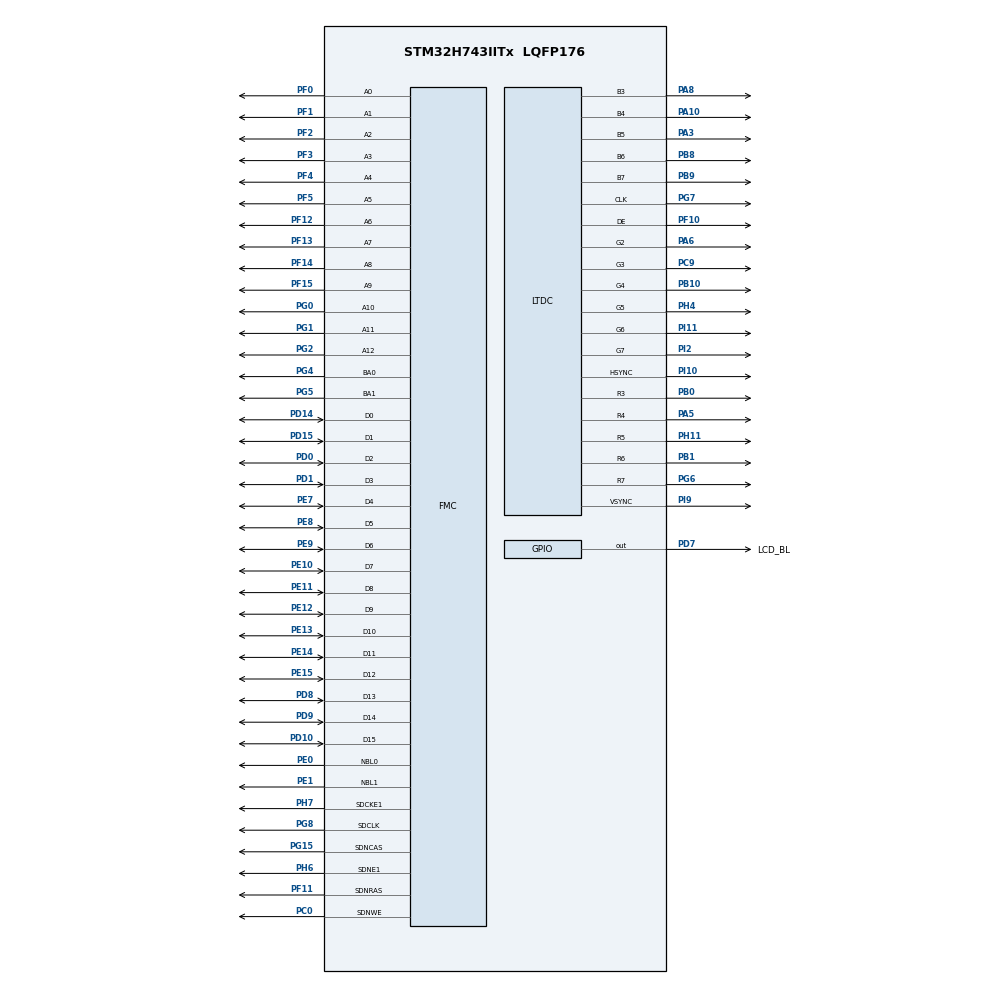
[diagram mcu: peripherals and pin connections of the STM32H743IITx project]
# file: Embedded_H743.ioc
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CORTEX_M7.default_mode_Activation=1
DMA2D.ColorMode=DMA2D_OUTPUT_RGB565
FMC.ColumnBitsNumber2=FMC_SDRAM_COLUMN_BITS_NUM_9
FMC.ExitSelfRefreshDelay2=9
FMC.LoadToActiveDelay2=2
FMC.RCDDelay2=3
FMC.RPDelay1=3
FMC.RPDelay2=3
FMC.RowCycleDelay1=8
FMC.RowCycleDelay2=8
FMC.SDClockPeriod1=FMC_SDRAM_CLOCK_PERIOD_3
FMC.SDClockPeriod2=FMC_SDRAM_CLOCK_PERIOD_3
FMC.SelfRefreshTime2=6
FMC.WriteRecoveryTime2=3
FREERTOS.Tasks01=taskTouchGFX,24,2048,TouchGFX_Task,As weak,NULL,Dynamic,NULL,NULL
FREERTOS.configTOTAL_HEAP_SIZE=32768
FREERTOS.configUSE_NEWLIB_REENTRANT=1
LTDC.ActiveH=272
LTDC.ActiveW=480
LTDC.Alpha_L0=255
LTDC.FBStartAdress_L0=0xD2000000
LTDC.HBP=8
LTDC.HFP=4
LTDC.HSync=41
LTDC.ImageHeight_L0=272
LTDC.ImageWidth_L0=480
LTDC.Layers=0
LTDC.PixelFormat_L0=LTDC_PIXEL_FORMAT_RGB565
LTDC.VFP=4
LTDC.VSync=1
LTDC.WindowX1_L0=480
LTDC.WindowY1_L0=272
Mcu.Family=STM32H7
Mcu.Name=STM32H743IITx
Mcu.Package=LQFP176
Mcu.UserConstants=TOUCHGFX_BUFFER_START_ADDR_1,0xD2000000;TOUCHGFX_BUFFER_START_ADDR_2,0xD2261120
NVIC.DMA2D_IRQn=true\:9\:0\:true\:false\:true\:true\:true\:true\:true
NVIC.LTDC_IRQn=true\:9\:0\:true\:false\:true\:true\:true\:true\:true
NVIC.PriorityGroup=NVIC_PRIORITYGROUP_4
NVIC.TIM6_DAC_IRQn=true\:15\:0\:false\:false\:true\:false\:false\:true\:true
NVIC.TimeBase=TIM6_DAC_IRQn
NVIC.TimeBaseIP=TIM6
PA10.GPIO_Mode=GPIO_MODE_AF_PP
PA10.GPIO_PuPd=GPIO_NOPULL
PA10.GPIO_Speed=GPIO_SPEED_FREQ_VERY_HIGH
PA10.Mode=RGB565
PA10.Signal=LTDC_B4
PA13\ (JTMS/SWDIO).Mode=Serial_Wire
PA13\ (JTMS/SWDIO).Signal=DEBUG_JTMS-SWDIO
PA14\ (JTCK/SWCLK).Mode=Serial_Wire
PA14\ (JTCK/SWCLK).Signal=DEBUG_JTCK-SWCLK
PA3.GPIO_Mode=GPIO_MODE_AF_PP
PA3.GPIO_PuPd=GPIO_NOPULL
PA3.GPIO_Speed=GPIO_SPEED_FREQ_VERY_HIGH
PA3.Mode=RGB565
PA3.Signal=LTDC_B5
PA5.GPIO_Mode=GPIO_MODE_AF_PP
PA5.GPIO_PuPd=GPIO_NOPULL
PA5.GPIO_Speed=GPIO_SPEED_FREQ_VERY_HIGH
PA5.Mode=RGB565
PA5.Signal=LTDC_R4
PA6.GPIO_Mode=GPIO_MODE_AF_PP
PA6.GPIO_PuPd=GPIO_NOPULL
PA6.GPIO_Speed=GPIO_SPEED_FREQ_VERY_HIGH
PA6.Mode=RGB565
PA6.Signal=LTDC_G2
PA8.GPIO_Mode=GPIO_MODE_AF_PP
PA8.GPIO_PuPd=GPIO_NOPULL
PA8.GPIO_Speed=GPIO_SPEED_FREQ_VERY_HIGH
PA8.Mode=RGB565
PA8.Signal=LTDC_B3
PB0.GPIO_Mode=GPIO_MODE_AF_PP
PB0.GPIO_PuPd=GPIO_NOPULL
PB0.GPIO_Speed=GPIO_SPEED_FREQ_VERY_HIGH
PB0.Mode=RGB565
PB0.Signal=LTDC_R3
PB1.GPIO_Mode=GPIO_MODE_AF_PP
PB1.GPIO_PuPd=GPIO_NOPULL
PB1.GPIO_Speed=GPIO_SPEED_FREQ_VERY_HIGH
PB1.Mode=RGB565
PB1.Signal=LTDC_R6
PB10.GPIO_Mode=GPIO_MODE_AF_PP
PB10.GPIO_PuPd=GPIO_NOPULL
PB10.GPIO_Speed=GPIO_SPEED_FREQ_VERY_HIGH
PB10.Mode=RGB565
PB10.Signal=LTDC_G4
PB8.GPIO_Mode=GPIO_MODE_AF_PP
PB8.GPIO_PuPd=GPIO_NOPULL
PB8.GPIO_Speed=GPIO_SPEED_FREQ_VERY_HIGH
PB8.Mode=RGB565
PB8.Signal=LTDC_B6
PB9.GPIO_Mode=GPIO_MODE_AF_PP
PB9.GPIO_PuPd=GPIO_NOPULL
PB9.GPIO_Speed=GPIO_SPEED_FREQ_VERY_HIGH
PB9.Mode=RGB565
PB9.Signal=LTDC_B7
PC0.Signal=FMC_SDNWE
PC14-OSC32_IN\ (OSC32_IN).Mode=LSE-External-Oscillator
PC14-OSC32_IN\ (OSC32_IN).Signal=RCC_OSC32_IN
PC15-OSC32_OUT\ (OSC32_OUT).Mode=LSE-External-Oscillator
PC15-OSC32_OUT\ (OSC32_OUT).Signal=RCC_OSC32_OUT
PC9.GPIO_Mode=GPIO_MODE_AF_PP
PC9.GPIO_PuPd=GPIO_NOPULL
PC9.GPIO_Speed=GPIO_SPEED_FREQ_VERY_HIGH
PC9.Mode=RGB565
PC9.Signal=LTDC_G3
PD0.Signal=FMC_D2_DA2
PD1.Signal=FMC_D3_DA3
PD10.Signal=FMC_D15_DA15
PD14.Signal=FMC_D0_DA0
PD15.Signal=FMC_D1_DA1
PD7.GPIO_Label=LCD_BL
PD7.GPIO_PuPd=GPIO_PULLUP
PD7.GPIO_Speed=GPIO_SPEED_FREQ_HIGH
PD7.PinState=GPIO_PIN_RESET
PD7.Signal=GPIO_Output
PD8.Signal=FMC_D13_DA13
PD9.Signal=FMC_D14_DA14
PE0.Signal=FMC_NBL0
PE1.Signal=FMC_NBL1
PE10.Signal=FMC_D7_DA7
PE11.Signal=FMC_D8_DA8
PE12.Signal=FMC_D9_DA9
PE13.Signal=FMC_D10_DA10
PE14.Signal=FMC_D11_DA11
PE15.Signal=FMC_D12_DA12
PE7.Signal=FMC_D4_DA4
PE8.Signal=FMC_D5_DA5
PE9.Signal=FMC_D6_DA6
PF0.Signal=FMC_A0
PF1.Signal=FMC_A1
PF10.GPIO_Mode=GPIO_MODE_AF_PP
PF10.GPIO_PuPd=GPIO_NOPULL
PF10.GPIO_Speed=GPIO_SPEED_FREQ_VERY_HIGH
PF10.Mode=RGB565
PF10.Signal=LTDC_DE
PF11.Signal=FMC_SDNRAS
PF12.Signal=FMC_A6
PF13.Signal=FMC_A7
PF14.Signal=FMC_A8
PF15.Signal=FMC_A9
PF2.Signal=FMC_A2
PF3.Signal=FMC_A3
PF4.Signal=FMC_A4
PF5.Signal=FMC_A5
PG0.Signal=FMC_A10
PG1.Signal=FMC_A11
PG15.Signal=FMC_SDNCAS
PG2.Signal=FMC_A12
PG4.Signal=FMC_A14_BA0
PG5.Signal=FMC_A15_BA1
PG6.Mode=RGB565
PG6.Signal=LTDC_R7
PG7.Mode=RGB565
PG7.Signal=LTDC_CLK
PG8.Signal=FMC_SDCLK
PH0-OSC_IN\ (PH0).Mode=HSE-External-Oscillator
PH0-OSC_IN\ (PH0).Signal=RCC_OSC_IN
PH1-OSC_OUT\ (PH1).Mode=HSE-External-Oscillator
PH1-OSC_OUT\ (PH1).Signal=RCC_OSC_OUT
PH11.Mode=RGB565
PH11.Signal=LTDC_R5
PH4.Mode=RGB565
PH4.Signal=LTDC_G5
PH6.Mode=SdramChipSelect2_2
PH6.Signal=FMC_SDNE1
PH7.Mode=SdramChipSelect2_2
PH7.Signal=FMC_SDCKE1
PI10.Mode=RGB565
PI10.Signal=LTDC_HSYNC
PI11.Mode=RGB565
PI11.Signal=LTDC_G6
PI2.Mode=RGB565
PI2.Signal=LTDC_G7
PI9.Mode=RGB565
PI9.Signal=LTDC_VSYNC
ProjectManager.HeapSize=0x800
ProjectManager.StackSize=0x1000
ProjectManager.TargetToolchain=STM32CubeIDE
RCC.ADCFreq_Value=50390625
RCC.APB1Freq_Value=75000000
RCC.APB2Freq_Value=75000000
RCC.APB3Freq_Value=75000000
RCC.APB4Freq_Value=75000000
RCC.CortexFreq_Value=300000000
RCC.D1PPRE=RCC_APB3_DIV2
RCC.D2PPRE1=RCC_APB1_DIV2
RCC.D2PPRE2=RCC_APB2_DIV2
RCC.D3PPRE=RCC_APB4_DIV2
RCC.DIVM1=8
RCC.DIVN1=192
RCC.DIVN3=192
RCC.DIVR3=3
RCC.EnbaleCSS=true
RCC.HCLKFreq_Value=150000000
RCC.HPRE=RCC_HCLK_DIV2
RCC.PLLSourceVirtual=RCC_PLLSOURCE_HSE
RCC.SYSCLKFreq_VALUE=300000000
RCC.SYSCLKSource=RCC_SYSCLKSOURCE_PLLCLK
RCC.USBFreq_Value=300000000
SH.FMC_A0.0=FMC_A0,13b-sda2
SH.FMC_A1.0=FMC_A1,13b-sda2
SH.FMC_A10.0=FMC_A10,13b-sda2
SH.FMC_A11.0=FMC_A11,13b-sda2
SH.FMC_A12.0=FMC_A12,13b-sda2
SH.FMC_A14_BA0.0=FMC_BA0,FourSdramBanks2
SH.FMC_A15_BA1.0=FMC_BA1,FourSdramBanks2
SH.FMC_A2.0=FMC_A2,13b-sda2
SH.FMC_A3.0=FMC_A3,13b-sda2
SH.FMC_A4.0=FMC_A4,13b-sda2
SH.FMC_A5.0=FMC_A5,13b-sda2
SH.FMC_A6.0=FMC_A6,13b-sda2
SH.FMC_A7.0=FMC_A7,13b-sda2
SH.FMC_A8.0=FMC_A8,13b-sda2
SH.FMC_A9.0=FMC_A9,13b-sda2
SH.FMC_D0_DA0.0=FMC_D0,sd-16b-d2
SH.FMC_D10_DA10.0=FMC_D10,sd-16b-d2
SH.FMC_D11_DA11.0=FMC_D11,sd-16b-d2
SH.FMC_D12_DA12.0=FMC_D12,sd-16b-d2
SH.FMC_D13_DA13.0=FMC_D13,sd-16b-d2
SH.FMC_D14_DA14.0=FMC_D14,sd-16b-d2
SH.FMC_D15_DA15.0=FMC_D15,sd-16b-d2
SH.FMC_D1_DA1.0=FMC_D1,sd-16b-d2
SH.FMC_D2_DA2.0=FMC_D2,sd-16b-d2
SH.FMC_D3_DA3.0=FMC_D3,sd-16b-d2
SH.FMC_D4_DA4.0=FMC_D4,sd-16b-d2
SH.FMC_D5_DA5.0=FMC_D5,sd-16b-d2
SH.FMC_D6_DA6.0=FMC_D6,sd-16b-d2
SH.FMC_D7_DA7.0=FMC_D7,sd-16b-d2
SH.FMC_D8_DA8.0=FMC_D8,sd-16b-d2
SH.FMC_D9_DA9.0=FMC_D9,sd-16b-d2
SH.FMC_NBL0.0=FMC_NBL0,Sd2ByteEnable2
SH.FMC_NBL1.0=FMC_NBL1,Sd2ByteEnable2
SH.FMC_SDCLK.0=FMC_SDCLK,13b-sda2
SH.FMC_SDNCAS.0=FMC_SDNCAS,13b-sda2
SH.FMC_SDNRAS.0=FMC_SDNRAS,13b-sda2
SH.FMC_SDNWE.0=FMC_SDNWE,13b-sda2
VP_CRC_VS_CRC.Mode=CRC_Activate
VP_DMA2D_VS_DMA2D.Mode=DMA2D_Activate
VP_FATFS_VS_Generic.Mode=User_defined
VP_FREERTOS_VS_CMSIS_V2.Mode=CMSIS_V2
VP_SYS_VS_tim6.Mode=TIM6
board=custom

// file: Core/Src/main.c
/* USER CODE BEGIN Header */
/**
  ******************************************************************************
  * @file           : main.c
  * @brief          : Main program body
  ******************************************************************************
  * @attention
  *
  * Copyright (c) 2022 STMicroelectronics.
  * All rights reserved.
  *
  * This software is licensed under terms that can be found in the LICENSE file
  * in the root directory of this software component.
  * If no LICENSE file comes with this software, it is provided AS-IS.
  *
  ******************************************************************************
  */
/* USER CODE END Header */
#include "main.h"
#include "cmsis_os.h"
#include "crc.h"
#include "dma2d.h"
#include "fatfs.h"
#include "ltdc.h"
#include "gpio.h"
#include "fmc.h"

/* USER CODE BEGIN Includes */
#include "user.h"
/* USER CODE END Includes */

void SystemClock_Config(void);
static void MPU_Config(void);
void MX_FREERTOS_Init(void);

int main(void)
{

  /* MPU Configuration--------------------------------------------------------*/
  MPU_Config();

  /* MCU Configuration--------------------------------------------------------*/

  /* Reset of all peripherals, Initializes the Flash interface and the Systick. */
  HAL_Init();

  /* Configure the system clock */
  SystemClock_Config();

  /* Initialize all configured peripherals */
  MX_GPIO_Init();
  MX_FATFS_Init();
  MX_DMA2D_Init();
  MX_FMC_Init();
  MX_CRC_Init();
  MX_LTDC_Init();

  /* Init scheduler */
  osKernelInitialize();  /* Call init function for freertos objects (in freertos.c) */
  MX_FREERTOS_Init();

  /* Start scheduler */
  osKernelStart();

  /* We should never get here as control is now taken by the scheduler */
  /* Infinite loop */
  /* USER CODE BEGIN WHILE */
  Main();
  while (1)
  {
    /* USER CODE END WHILE */

  }
}

void SystemClock_Config(void)
{
  RCC_OscInitTypeDef RCC_OscInitStruct = {0};
  RCC_ClkInitTypeDef RCC_ClkInitStruct = {0};

  /** Supply configuration update enable
  */
  HAL_PWREx_ConfigSupply(PWR_LDO_SUPPLY);

  /** Configure the main internal regulator output voltage
  */
  __HAL_PWR_VOLTAGESCALING_CONFIG(PWR_REGULATOR_VOLTAGE_SCALE2);

  while(!__HAL_PWR_GET_FLAG(PWR_FLAG_VOSRDY)) {}

  /** Macro to configure the PLL clock source
  */
  __HAL_RCC_PLL_PLLSOURCE_CONFIG(RCC_PLLSOURCE_HSE);

  /** Initializes the RCC Oscillators according to the specified parameters
  * in the RCC_OscInitTypeDef structure.
  */
  RCC_OscInitStruct.OscillatorType = RCC_OSCILLATORTYPE_HSE;
  RCC_OscInitStruct.HSEState = RCC_HSE_ON;
  RCC_OscInitStruct.PLL.PLLState = RCC_PLL_ON;
  RCC_OscInitStruct.PLL.PLLSource = RCC_PLLSOURCE_HSE;
  RCC_OscInitStruct.PLL.PLLM = 8;
  RCC_OscInitStruct.PLL.PLLN = 192;
  RCC_OscInitStruct.PLL.PLLP = 2;
  RCC_OscInitStruct.PLL.PLLQ = 2;
  RCC_OscInitStruct.PLL.PLLR = 2;
  RCC_OscInitStruct.PLL.PLLRGE = RCC_PLL1VCIRANGE_1;
  RCC_OscInitStruct.PLL.PLLVCOSEL = RCC_PLL1VCOWIDE;
  RCC_OscInitStruct.PLL.PLLFRACN = 0;
  if (HAL_RCC_OscConfig(&RCC_OscInitStruct) != HAL_OK)
  {
    Error_Handler();
  }

  /** Initializes the CPU, AHB and APB buses clocks
  */
  RCC_ClkInitStruct.ClockType = RCC_CLOCKTYPE_HCLK|RCC_CLOCKTYPE_SYSCLK
                              |RCC_CLOCKTYPE_PCLK1|RCC_CLOCKTYPE_PCLK2
                              |RCC_CLOCKTYPE_D3PCLK1|RCC_CLOCKTYPE_D1PCLK1;
  RCC_ClkInitStruct.SYSCLKSource = RCC_SYSCLKSOURCE_PLLCLK;
  RCC_ClkInitStruct.SYSCLKDivider = RCC_SYSCLK_DIV1;
  RCC_ClkInitStruct.AHBCLKDivider = RCC_HCLK_DIV2;
  RCC_ClkInitStruct.APB3CLKDivider = RCC_APB3_DIV2;
  RCC_ClkInitStruct.APB1CLKDivider = RCC_APB1_DIV2;
  RCC_ClkInitStruct.APB2CLKDivider = RCC_APB2_DIV2;
  RCC_ClkInitStruct.APB4CLKDivider = RCC_APB4_DIV2;

  if (HAL_RCC_ClockConfig(&RCC_ClkInitStruct, FLASH_LATENCY_2) != HAL_OK)
  {
    Error_Handler();
  }

  /** Enables the Clock Security System
  */
  HAL_RCC_EnableCSS();
}

/* MPU Configuration */

void MPU_Config(void)
{
  MPU_Region_InitTypeDef MPU_InitStruct = {0};

  /* Disables the MPU */
  HAL_MPU_Disable();

  /** Initializes and configures the Region and the memory to be protected
  */
  MPU_InitStruct.Enable = MPU_REGION_ENABLE;
  MPU_InitStruct.Number = MPU_REGION_NUMBER0;
  MPU_InitStruct.BaseAddress = 0x0;
  MPU_InitStruct.Size = MPU_REGION_SIZE_4GB;
  MPU_InitStruct.SubRegionDisable = 0x87;
  MPU_InitStruct.TypeExtField = MPU_TEX_LEVEL0;
  MPU_InitStruct.AccessPermission = MPU_REGION_NO_ACCESS;
  MPU_InitStruct.DisableExec = MPU_INSTRUCTION_ACCESS_DISABLE;
  MPU_InitStruct.IsShareable = MPU_ACCESS_SHAREABLE;
  MPU_InitStruct.IsCacheable = MPU_ACCESS_NOT_CACHEABLE;
  MPU_InitStruct.IsBufferable = MPU_ACCESS_NOT_BUFFERABLE;

  HAL_MPU_ConfigRegion(&MPU_InitStruct);
  /* Enables the MPU */
  HAL_MPU_Enable(MPU_PRIVILEGED_DEFAULT);

}

void HAL_TIM_PeriodElapsedCallback(TIM_HandleTypeDef *htim)
{
  if (htim->Instance == TIM6) {
    HAL_IncTick();
  }
}

void Error_Handler(void)
{
  __disable_irq();
  while (1)
  {
  }
}

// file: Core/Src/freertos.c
/* USER CODE BEGIN Header */
/**
  ******************************************************************************
  * File Name          : freertos.c
  * Description        : Code for freertos applications
  ******************************************************************************
  * @attention
  *
  * Copyright (c) 2022 STMicroelectronics.
  * All rights reserved.
  *
  * This software is licensed under terms that can be found in the LICENSE file
  * in the root directory of this software component.
  * If no LICENSE file comes with this software, it is provided AS-IS.
  *
  ******************************************************************************
  */
/* USER CODE END Header */

#include "FreeRTOS.h"
#include "task.h"
#include "main.h"
#include "cmsis_os.h"

/* Definitions for taskTouchGFX */
osThreadId_t taskTouchGFXHandle;
const osThreadAttr_t taskTouchGFX_attributes = {
  .name = "taskTouchGFX",
  .stack_size = 2048 * 4,
  .priority = (osPriority_t) osPriorityNormal,
};

void TouchGFX_Task(void *argument);

void MX_FREERTOS_Init(void); /* (MISRA C 2004 rule 8.1) */

void MX_FREERTOS_Init(void) {

  /* Create the thread(s) */
  /* creation of taskTouchGFX */
  taskTouchGFXHandle = osThreadNew(TouchGFX_Task, NULL, &taskTouchGFX_attributes);

}

__weak void TouchGFX_Task(void *argument)
{
  for(;;)
  {
    osDelay(1);
  }
}
